# STM32C542 register map
File version: 1.0.0
CPU: CM33 r0p4, little endian, MPU, FPU, 4 interrupt priority bits
Registers are 32-bit, read-write, reset 0x0 unless marked. A register's access mark holds for its fields unless they carry their own. Offsets are from the block's base; [hi:lo] are bit positions; {n}, {i} and the like mark numbered series; 'fields as' and 'values as' point back to an identical list.

## EXTI — EXTI register block
Base 0x44022000
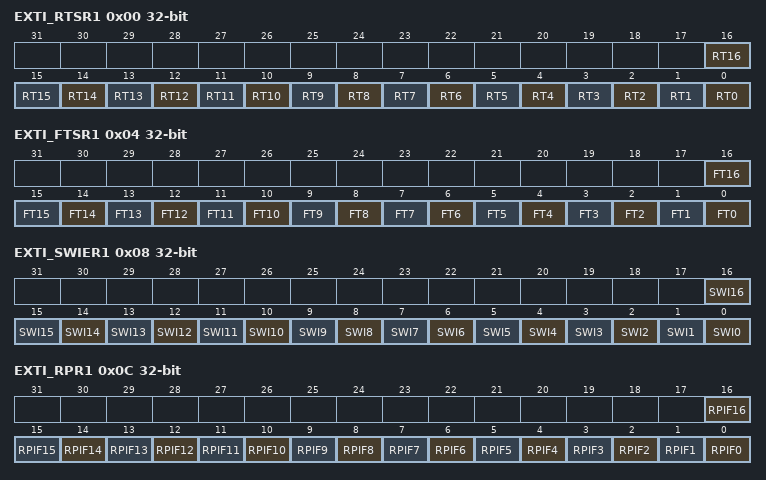
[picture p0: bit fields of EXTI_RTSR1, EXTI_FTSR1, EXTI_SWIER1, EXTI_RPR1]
0x00 EXTI_RTSR1 — EXTI rising trigger selection register
  [all] fields
    0=Rising trigger disabled (for event and interrupt) for input line; 1=Rising trigger enabled (for event and interrupt) for input line
  [n] RT{n} (n=0..16) — Rising trigger event configuration bit of configurable event input x
0x04 EXTI_FTSR1 — EXTI falling trigger selection register
  [all] fields
    0=Falling trigger disabled (for event and Interrupt) for input line; 1=Falling trigger enabled (for event and Interrupt) for input line
  [n] FT{n} (n=0..16) — Falling trigger event configuration bit of configurable event input x
0x08 EXTI_SWIER1 — EXTI software interrupt event register
  [all] fields
    0=Writing 0 has no effect; 1=Writing 1 triggers a rising edge event on event x. This bit is auto cleared by hardware.
  [n] SWI{n} (n=0..16) — Software interrupt on event x
0x0C EXTI_RPR1 — EXTI rising edge pending register
  [all] fields
    0=No rising edge trigger request occurred; 1=Rising edge trigger request occurred
  [n] RPIF{n} (n=0..16) — configurable event inputs x rising edge pending bit
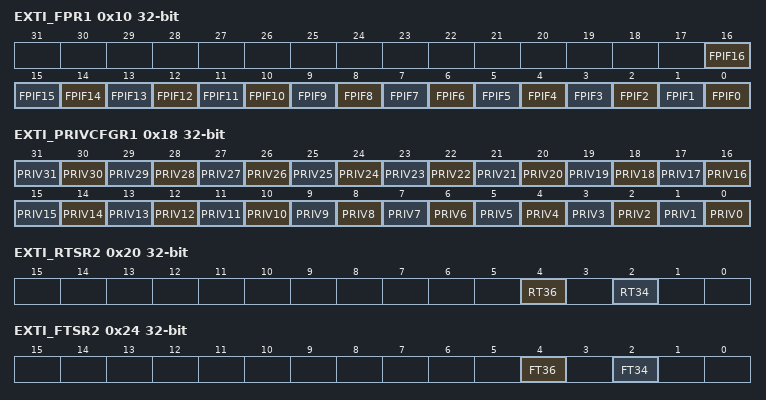
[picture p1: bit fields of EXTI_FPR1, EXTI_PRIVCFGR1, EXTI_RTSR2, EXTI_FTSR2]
0x10 EXTI_FPR1 — EXTI falling edge pending register
  [all] fields
    0=No falling edge trigger request occurred; 1=Falling edge trigger request occurred
  [n] FPIF{n} (n=0..16) — configurable event inputs x falling edge pending bit
0x18 EXTI_PRIVCFGR1 — EXTI privilege configuration register
  [all] fields
    0=Event privilege disabled (unprivileged); 1=Event privilege enabled (privileged)
  [n] PRIV{n} (n=0..31) — Privilege enable on event input x
0x20 EXTI_RTSR2 — EXTI rising trigger selection register 2
  [4] RT36 — Rising trigger event configuration bit of configurable event input 36less thansup>(1)less than/sup>
    values as the fields of EXTI_RTSR1
  [2] RT34 — Rising trigger event configuration bit of configurable event input 34less thansup>(1)less than/sup>
    values as the fields of EXTI_RTSR1
0x24 EXTI_FTSR2 — EXTI falling trigger selection register 2
  [4] FT36 — Falling trigger event configuration bit of configurable event input 36less thansup>(1)less than/sup>
    values as the fields of EXTI_FTSR1
  [2] FT34 — Falling trigger event configuration bit of configurable event input 34less thansup>(1)less than/sup>
    values as the fields of EXTI_FTSR1
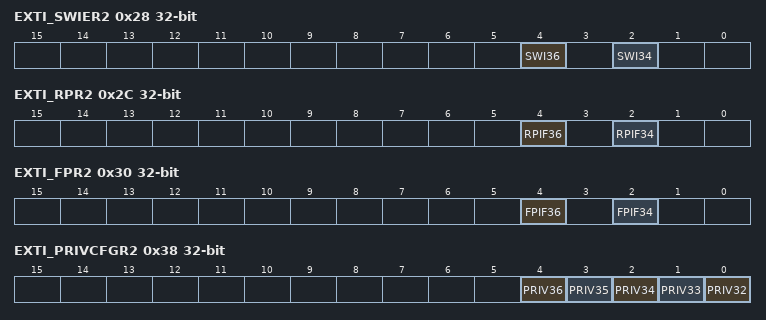
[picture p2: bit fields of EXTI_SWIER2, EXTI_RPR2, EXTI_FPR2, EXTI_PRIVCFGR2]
0x28 EXTI_SWIER2 — EXTI software interrupt event register 2
  [4] SWI36 — Software interrupt on event 36
    0=Writing 0 has no effect; 1=Writing 1 triggers a rising edge event on event 36. This bit is auto cleared by hardware.
  [2] SWI34 — Software interrupt on event 34
    0=Writing 0 has no effect; 1=Writing 1 triggers a rising edge event on event 34. This bit is auto cleared by hardware.
0x2C EXTI_RPR2 — EXTI rising edge pending register 2
  [4] RPIF36 — configurable event inputs 36 rising edge pending bit
    values as the fields of EXTI_RPR1
  [2] RPIF34 — configurable event inputs 34 rising edge pending bit
    values as the fields of EXTI_RPR1
0x30 EXTI_FPR2 — EXTI falling edge pending register 2
  [4] FPIF36 — configurable event inputs x falling edge pending bit
    values as the fields of EXTI_FPR1
  [2] FPIF34 — configurable event inputs x falling edge pending bit
    values as the fields of EXTI_FPR1
0x38 EXTI_PRIVCFGR2 — EXTI privilege configuration register 2
  [all] fields
    values as the fields of EXTI_PRIVCFGR1
  [n-32] PRIV{n} (n=32..36) — Privilege enable on event input x
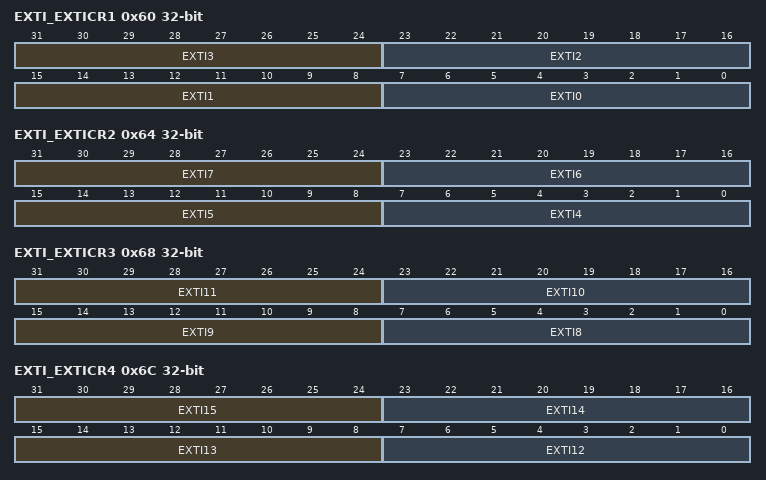
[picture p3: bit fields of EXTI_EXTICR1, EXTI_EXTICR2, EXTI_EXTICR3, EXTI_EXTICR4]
0x60 EXTI_EXTICR1 — EXTI external interrupt selection register
  [31:24] EXTI3 — EXTI3 GPIO port selection
    0=PA[3] pin; 1=PB[3] pin; 2=PC[3] pin
  [23:16] EXTI2 — EXTI2 GPIO port selection
    0=PA[2] pin; 1=PB[2] pin; 2=PC[2] pin; 3=PD[2] pin; 4=PE[2] pin; 7=PH[2] pin
  [15:8] EXTI1 — EXTI1 GPIO port selection
    0=PA[1] pin; 1=PB[1] pin; 2=PC[1] pin; 4=PE[1] pin; 7=PH[1] pin
  [7:0] EXTI0 — EXTI0 GPIO port selection
    0=PA[0] pin; 1=PB[0] pin; 2=PC[0] pin; 4=PE[0] pin; 7=PH[0] pin
0x64 EXTI_EXTICR2 — EXTI external interrupt selection register
  [31:24] EXTI7 — EXTI7 GPIO port selection
    0=PA[7] pin; 1=PB[7] pin; 2=PC[7] pin; 4=PE[7] pin
  [23:16] EXTI6 — EXTI6 GPIO port selection
    0=PA[6] pin; 1=PB[6] pin; 2=PC[6] pin
  [15:8] EXTI5 — EXTI5 GPIO port selection
    0=PA[5] pin; 1=PB[5] pin; 2=PC[5] pin; 3=PD[5] pin
  [7:0] EXTI4 — EXTI4 GPIO port selection
    0=PA[4] pin; 1=PB[4] pin; 2=PC[4] pin
0x68 EXTI_EXTICR3 — EXTI external interrupt selection register
  [31:24] EXTI11 — EXTI11 GPIO port selection
    0=PA[11] pin; 2=PC[11] pin; 3=PD[11] pin
  [23:16] EXTI10 — EXTI10 GPIO port selection
    0=PA[10] pin; 1=PB[10] pin; 2=PC[10] pin
  [15:8] EXTI9 — EXTI9 GPIO port selection
    0=PA[9] pin; 1=PB[9] pin; 2=PC[9] pin
  [7:0] EXTI8 — EXTI8 GPIO port selection
    0=PA[8] pin; 1=PB[8] pin; 2=PC[8] pin
0x6C EXTI_EXTICR4 — EXTI external interrupt selection register
  [31:24] EXTI15 — EXTI15 GPIO port selection
    0=PA[15] pin; 1=PB[15] pin; 2=PC[15] pin
  [23:16] EXTI14 — EXTI14 GPIO port selection
    0=PA[14] pin; 1=PB[14] pin; 2=PC[14] pin
  [15:8] EXTI13 — EXTI13 GPIO port selection
    0=PA[13] pin; 1=PB[13] pin; 2=PC[13] pin
  [7:0] EXTI12 — EXTI12 GPIO port selection
    0=PA[12] pin; 1=PB[12] pin; 2=PC[12] pin; 3=PD[12] pin
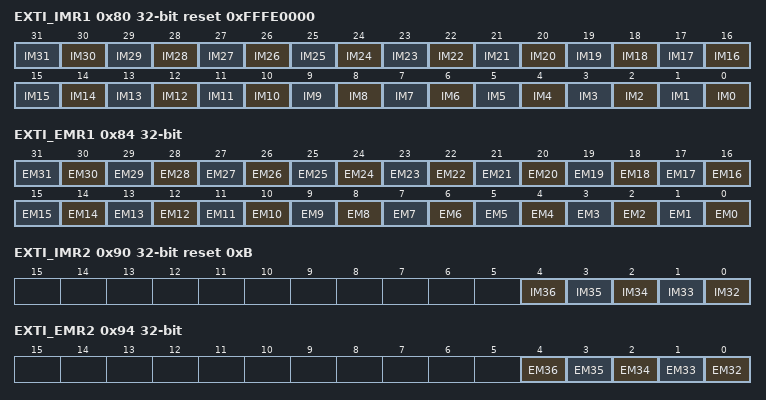
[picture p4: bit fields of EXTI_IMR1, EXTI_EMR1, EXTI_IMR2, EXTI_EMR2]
0x80 EXTI_IMR1 reset 0xFFFE0000 — EXTI CPU wake-up with interrupt mask register
  [all] fields
    0=Wake-up with interrupt request from input event x is masked; 1=Wake-up with interrupt request from input event x is unmasked
  [n] IM{n} (n=0..31) — CPU wake-up with interrupt mask on event input x
0x84 EXTI_EMR1 — EXTI CPU wake-up with event mask register
  [all] fields
    0=Wake-up with event generation from Line x is masked; 1=Wake-up with event generation from Line x is unmasked
  [n] EM{n} (n=0..31) — CPU wake-up with event generation mask on event input x
0x90 EXTI_IMR2 reset 0xB — EXTI CPU wake-up with interrupt mask register 2
  [all] fields
    values as the fields of EXTI_IMR1
  [n-32] IM{n} (n=32..36) — CPU wake-up with interrupt mask on event input x
0x94 EXTI_EMR2 — EXTI CPU wake-up with event mask register 2
  [all] fields
    values as the fields of EXTI_EMR1
  [n-32] EM{n} (n=32..36) — CPU wake-up with event generation mask on event input x

## Notices in the file
Copyright (c) 2026 STMicroelectronics.
SPDX-License-Identifier: Apache-2.0
Licensed under the Apache License, Version 2.0 (the "License");
you may not use this file except in compliance with the License.
You may obtain a copy of the License at
http://www.apache.org/licenses/LICENSE-2.0
Unless required by applicable law or agreed to in writing, software
distributed under the License is distributed on an "AS IS" BASIS,
WITHOUT WARRANTIES OR CONDITIONS OF ANY KIND, either express or implied.
See the License for the specific language governing permissions and
limitations under the License.
